# G32R501 register map
Vendor: Geehy Semiconductor Co., Ltd.; Series: G32R5; File version: 1.0
CPU: CM55 r0p1, little endian, MPU, FPU, double-precision FPU, DSP, VTOR, 4 interrupt priority bits
Registers are 32-bit, read-write, reset 0x0 unless marked. A register's access mark holds for its fields unless they carry their own. Offsets are from the block's base; [hi:lo] are bit positions; {n}, {i} and the like mark numbered series.

## GPIOCTRL — GPIO CTRL Registers
Base 0x40030000
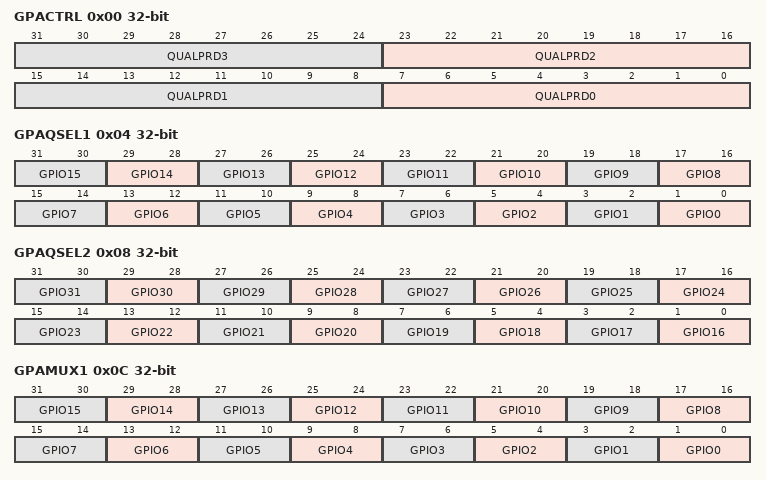
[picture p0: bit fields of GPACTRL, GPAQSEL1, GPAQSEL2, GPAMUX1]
0x00 GPACTRL — GPIO A Qualification Sampling Period (GPIO0 to GPIO31)
  [8n+7:8n] QUALPRD{n} (n=0..3) — GPIO{8n} to GPIO{8n+7} sampling cycle
0x04 GPAQSEL1 — GPIO A Qualification Type (GPIO0 to GPIO15)
  [2n+1:2n] GPIO{n} (n=0..15) — GPIO{n} Input type
0x08 GPAQSEL2 — GPIO A Qualification Type (GPIO16 to GPIO31)
  [2n-31:2n-32] GPIO{n} (n=16..31) — GPIO{n} Input type
0x0C GPAMUX1 — GPIO A Peripheral Mux (GPIO0 to GPIO15)
  [2n+1:2n] GPIO{n} (n=0..15) — GPIO{n} peripheral mux configuration in the low 2 bits
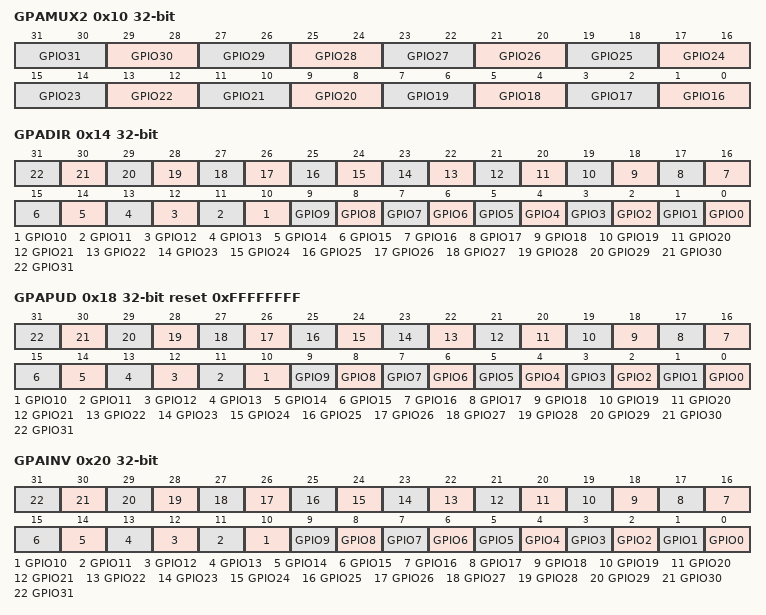
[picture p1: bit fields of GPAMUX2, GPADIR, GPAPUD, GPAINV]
0x10 GPAMUX2 — GPIO A Peripheral Mux (GPIO16 to GPIO31)
  [2n-31:2n-32] GPIO{n} (n=16..31) — GPIO{n} peripheral mux configuration in the low 2 bits
0x14 GPADIR — GPIO A Direction (GPIO0 to GPIO31)
  [n] GPIO{n} (n=0..31) — GPIO{n} Data direction
0x18 GPAPUD reset 0xFFFFFFFF — GPIO A Pull-Up Disable (GPIO0 to GPIO31)
  [n] GPIO{n} (n=0..31) — GPIO{n} Pull-up disable
0x20 GPAINV — GPIO A Input Inversion (GPIO0 to GPIO31)
  [n] GPIO{n} (n=0..31) — GPIO{n} Input inversion
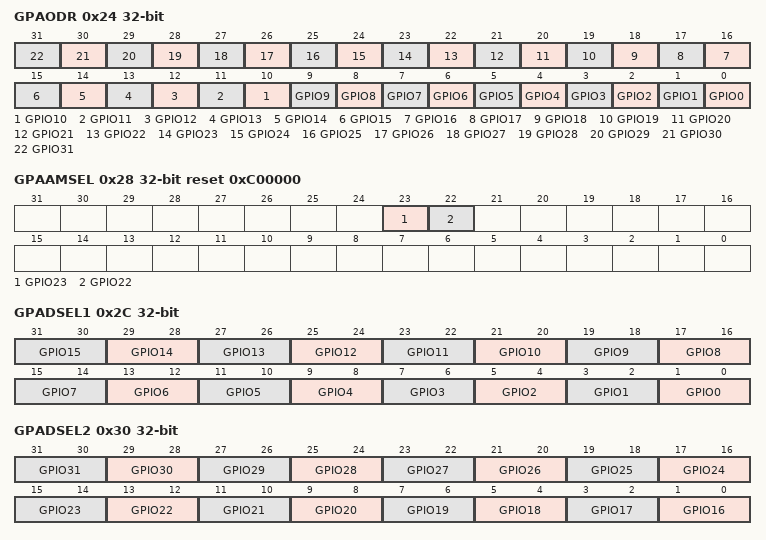
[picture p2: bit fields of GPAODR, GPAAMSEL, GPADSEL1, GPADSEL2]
0x24 GPAODR — GPIO A Open Drain Output Mode (GPIO0 to GPIO31)
  [n] GPIO{n} (n=0..31) — GPIO{n} Open-drain output mode
0x28 GPAAMSEL reset 0xC00000 — GPIO A Analog Mode Select (GPIO0 to GPIO31)
  [23] GPIO23 — Analog mode select for GPIO23
  [22] GPIO22 — Analog mode select for GPIO22
0x2C GPADSEL1 — GPIO A driver capability selection register 1
  [2n+1:2n] GPIO{n} (n=0..15) — Driver capability select for GPIO{n}
0x30 GPADSEL2 — GPIO A driver capability selection register 2
  [2n-31:2n-32] GPIO{n} (n=16..31) — Driver capability select for GPIO{n}
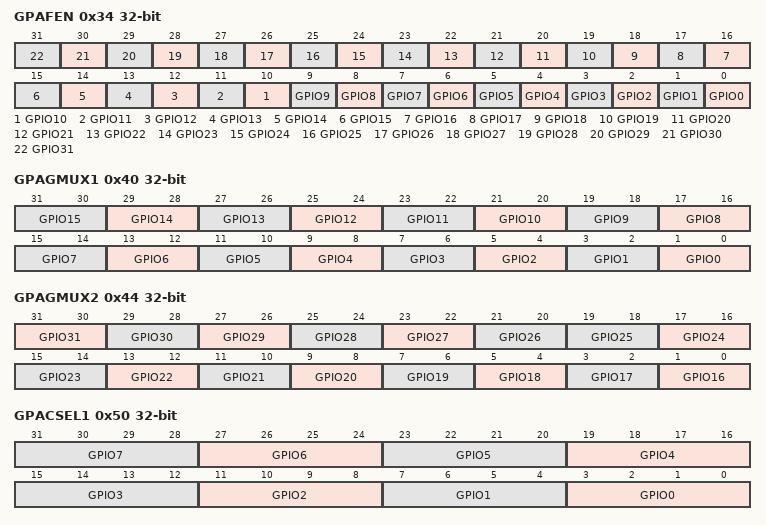
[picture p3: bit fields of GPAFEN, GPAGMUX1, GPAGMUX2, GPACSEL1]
0x34 GPAFEN — GPIO A maximum output frequency enable register
  [n] GPIO{n} (n=0..31) — GPIO{n} Maximum Output Frequency Enable
0x40 GPAGMUX1 — GPIO A Peripheral Group Mux (GPIO0 to GPIO15)
  [2n+1:2n] GPIO{n} (n=0..15) — GPIO{n} peripheral mux configuration in the High 2 bits
0x44 GPAGMUX2 — GPIO A Peripheral Group Mux (GPIO16 to GPIO31)
  [2n-31:2n-32] GPIO{n} (n=27..31) — GPIO{n} peripheral mux configuration in the High 2 bits
  [21:20] GPIO26 — GPIO126 peripheral mux configuration in the High 2 bits
  [2n-31:2n-32] GPIO{n} (n=16..25) — GPIO{n} peripheral mux configuration in the High 2 bits
0x50 GPACSEL1 — GPIO A Master Core Select (GPIO0 to GPIO7)
  [4n+3:4n] GPIO{n} (n=0..7) — GPIO{n} Master core select
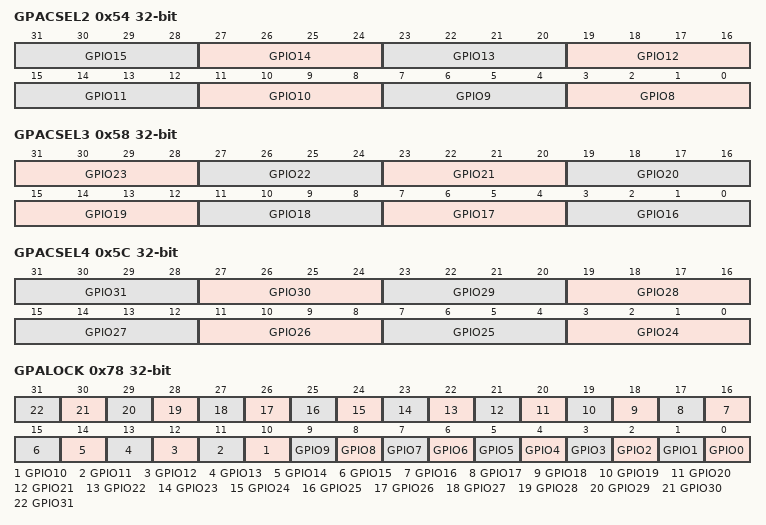
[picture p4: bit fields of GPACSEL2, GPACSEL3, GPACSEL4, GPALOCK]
0x54 GPACSEL2 — GPIO A Master Core Select (GPIO8 to GPIO15)
  [4n-29:4n-32] GPIO{n} (n=8..15) — GPIO{n} Master core select
0x58 GPACSEL3 — GPIO A Master Core Select (GPIO16 to GPIO23)
  [31:28] GPIO23 — GPIO22 Master core select
  [4n-61:4n-64] GPIO{n} (n=16..22) — GPIO{n} Master core select
0x5C GPACSEL4 — GPIO A Master Core Select (GPIO24 to GPIO31)
  [4n-93:4n-96] GPIO{n} (n=24..31) — GPIO{n} Master core select
0x78 GPALOCK — GPIO A Lock Register (GPIO0 to GPIO31)
  [n] GPIO{n} (n=0..31) — GPIO{n} Configuration lock
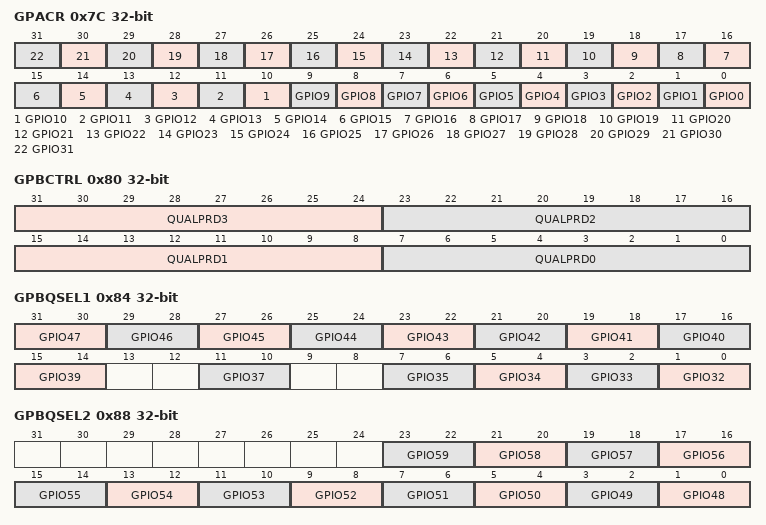
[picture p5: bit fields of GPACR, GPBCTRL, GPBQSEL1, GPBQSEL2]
0x7C GPACR — GPIO A Lock Commit Register (GPIO0 to GPIO31)
  [n] GPIO{n} (n=0..31) — GPIO{n} lock is locked
0x80 GPBCTRL — GPIO B Qualification Sampling Period (GPIO32 to GPIO59)
  [31:24] QUALPRD3 — GPIO56 to GPIO59 sampling cycle
  [23:16] QUALPRD2 — GPIO48 to GPIO55 sampling cycle
  [15:8] QUALPRD1 — GPIO40 to GPIO47 sampling cycle
  [7:0] QUALPRD0 — GPIO32 to GPIO39 sampling cycle
0x84 GPBQSEL1 — GPIO B Qualification Type (GPIO32 to GPIO47)
  [2n-63:2n-64] GPIO{n} (n=39..47) — GPIO{n} Input type
  [11:10] GPIO37 — GPIO37 Input type
  [2n-63:2n-64] GPIO{n} (n=32..35) — GPIO{n} Input type
0x88 GPBQSEL2 — GPIO B Qualification Type (GPIO48 to GPIO63)
  [2n-95:2n-96] GPIO{n} (n=48..59) — GPIO{n} Input type
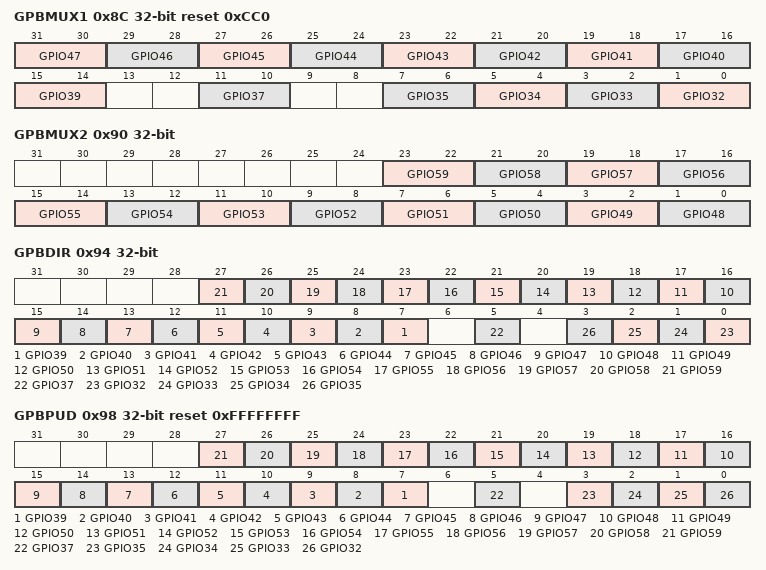
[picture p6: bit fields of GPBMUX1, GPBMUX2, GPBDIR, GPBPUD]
0x8C GPBMUX1 reset 0xCC0 — GPIO B Peripheral Mux (GPIO32 to GPIO47)
  [2n-63:2n-64] GPIO{n} (n=39..47) — GPIO{n} peripheral mux configuration in the low 2 bits
  [11:10] GPIO37 — GPIO37 peripheral mux configuration in the low 2 bits
  [2n-63:2n-64] GPIO{n} (n=32..35) — GPIO{n} peripheral mux configuration in the low 2 bits
0x90 GPBMUX2 — GPIO B Peripheral Mux (GPIO48 to GPIO63)
  [23:22] GPIO59 — GPIO4859 peripheral mux configuration in the low 2 bits
  [2n-95:2n-96] GPIO{n} (n=48..58) — GPIO{n} peripheral mux configuration in the low 2 bits
0x94 GPBDIR — GPIO B Direction (GPIO32 to GPIO59)
  [n-32] GPIO{n} (n=39..59) — GPIO{n} Data direction
  [5] GPIO37 — GPIO37 Data direction
  [n-32] GPIO{n} (n=32..35) — GPIO{n} Data direction
0x98 GPBPUD reset 0xFFFFFFFF — GPIO B Pull-Up Disable (GPIO32 to GPIO59)
  [n-32] GPIO{n} (n=39..59) — GPIO{n} Pull-up disable
  [5] GPIO37 — GPIO37 Pull-up disable
  [3] GPIO35 — GPIO35 Pull-up disable
  [2] GPIO34 — GPIO34 Pull-up disable
  [1] GPIO33 — GPIO32 Pull-up disable
  [0] GPIO32 — GPIO32 Pull-up disable
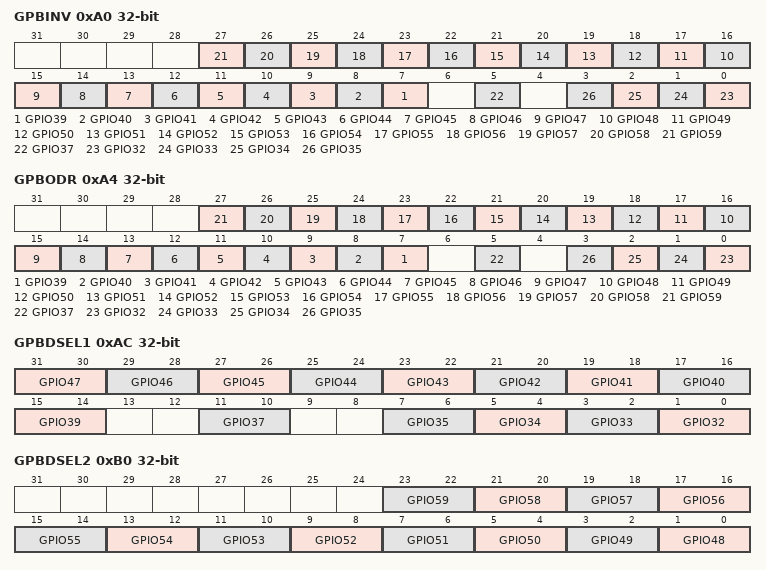
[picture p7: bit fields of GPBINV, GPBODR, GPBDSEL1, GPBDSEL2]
0xA0 GPBINV — GPIO B Input Inversion (GPIO32 to GPIO59)
  [n-32] GPIO{n} (n=39..59) — GPIO{n} Input inversion
  [5] GPIO37 — GPIO37 Input inversion
  [n-32] GPIO{n} (n=32..35) — GPIO{n} Input inversion
0xA4 GPBODR — GPIO B Open Drain Output Mode (GPIO32 to GPIO59)
  [n-32] GPIO{n} (n=39..59) — GPIO{n} Open-drain output mode
  [5] GPIO37 — GPIO37 Open-drain output mode
  [n-32] GPIO{n} (n=32..35) — GPIO{n} Open-drain output mode
0xAC GPBDSEL1 — GPIO B driver capability selection register 1
  [2n-63:2n-64] GPIO{n} (n=39..47) — Driver capability select for GPIO{n}
  [11:10] GPIO37 — Driver capability select for GPIO37
  [2n-63:2n-64] GPIO{n} (n=32..35) — Driver capability select for GPIO{n}
0xB0 GPBDSEL2 — GPIO B driver capability selection register 2
  [2n-95:2n-96] GPIO{n} (n=48..59) — Driver capability select for GPIO{n}
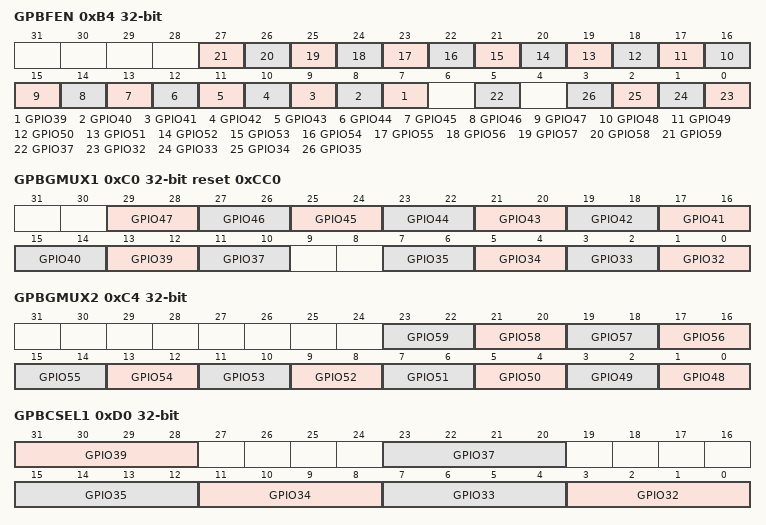
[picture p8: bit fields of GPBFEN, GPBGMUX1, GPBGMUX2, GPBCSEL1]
0xB4 GPBFEN — GPIO B maximum output frequency enable register
  [n-32] GPIO{n} (n=39..59) — GPIO{n} Maximum Output Frequency Enable
  [5] GPIO37 — GPIO37 Maximum Output Frequency Enable
  [n-32] GPIO{n} (n=32..35) — GPIO{n} Maximum Output Frequency Enable
0xC0 GPBGMUX1 reset 0xCC0 — GPIO B Peripheral Group Mux (GPIO32 to GPIO47)
  [2n-65:2n-66] GPIO{n} (n=39..47) — GPIO{n} peripheral mux configuration in the High 2 bits
  [11:10] GPIO37 — GPIO37 peripheral mux configuration in the High 2 bits
  [2n-63:2n-64] GPIO{n} (n=32..35) — GPIO{n} peripheral mux configuration in the High 2 bits
0xC4 GPBGMUX2 — GPIO B Peripheral Group Mux (GPIO48 to GPIO63)
  [2n-95:2n-96] GPIO{n} (n=48..59) — GPIO{n} peripheral mux configuration in the High 2 bits
0xD0 GPBCSEL1 — GPIO B Master Core Select (GPIO32 to GPIO39)
  [31:28] GPIO39 — GPIO39 Master core select
  [23:20] GPIO37 — GPIO37 Master core select
  [4n-125:4n-128] GPIO{n} (n=32..35) — GPIO{n} Master core select
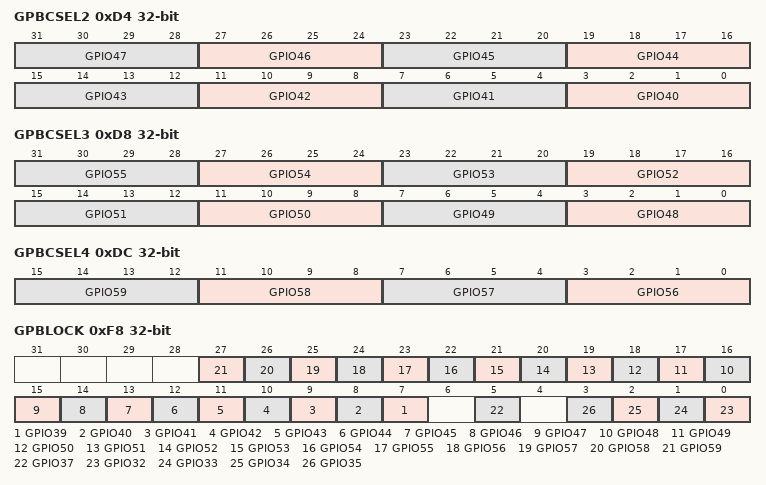
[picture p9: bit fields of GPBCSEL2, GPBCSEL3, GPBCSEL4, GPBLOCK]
0xD4 GPBCSEL2 — GPIO B Master Core Select (GPIO40 to GPIO47)
  [4n-157:4n-160] GPIO{n} (n=40..47) — GPIO{n} Master core select
0xD8 GPBCSEL3 — GPIO B Master Core Select (GPIO48 to GPIO55)
  [4n-189:4n-192] GPIO{n} (n=48..55) — GPIO{n} Master core select
0xDC GPBCSEL4 — GPIO B Master Core Select (GPIO56 to GPIO63)
  [4n-221:4n-224] GPIO{n} (n=56..59) — GPIO{n} Master core select
0xF8 GPBLOCK — GPIO B Lock Register (GPIO32 to GPIO59)
  [n-32] GPIO{n} (n=39..59) — GPIO{n} Configuration lock
  [5] GPIO37 — GPIO37 Configuration lock
  [n-32] GPIO{n} (n=32..35) — GPIO{n} Configuration lock
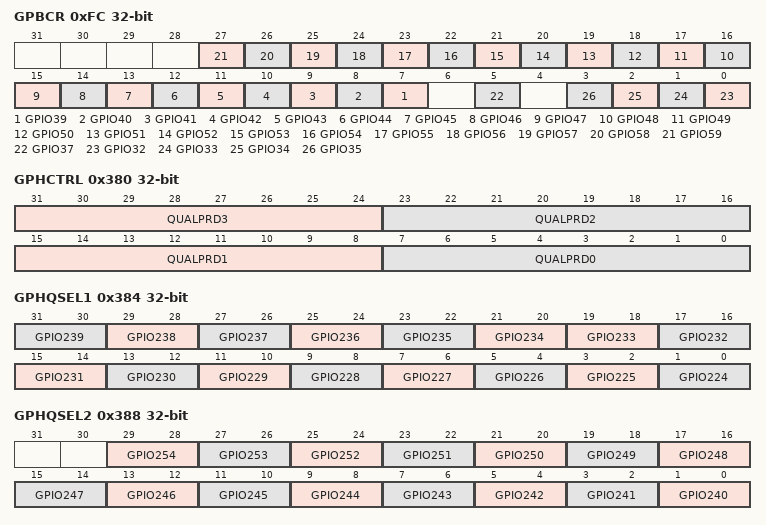
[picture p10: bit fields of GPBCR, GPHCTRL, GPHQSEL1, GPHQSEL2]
0xFC GPBCR — GPIO B Lock Commit Register (GPIO32 to GPIO59)
  [n-32] GPIO{n} (n=39..59) — GPIO{n} lock is locked
  [5] GPIO37 — GPIO37 lock is locked
  [n-32] GPIO{n} (n=32..35) — GPIO{n} lock is locked
0x380 GPHCTRL — GPIO H Qualification Sampling Period (GPIO224 to GPIO255)
  [31:24] QUALPRD3 — GPIO248 to GPIO254 sampling cycle
  [23:16] QUALPRD2 — GPIO240 to GPIO247 sampling cycle
  [15:8] QUALPRD1 — GPIO232 to GPIO239 sampling cycle
  [7:0] QUALPRD0 — GPIO224 to GPIO231 sampling cycle
0x384 GPHQSEL1 — GPIO H Qualification Type (GPIO224 to GPIO239)
  [2n-447:2n-448] GPIO{n} (n=234..239) — GPIO{n} Input type
  [19:18] GPIO233 — GPIO2333 Input type
  [2n-447:2n-448] GPIO{n} (n=224..232) — GPIO{n} Input type
0x388 GPHQSEL2 — GPIO H Qualification Type (GPIO240 to GPIO255)
  [2n-479:2n-480] GPIO{n} (n=240..254) — GPIO{n} Input type
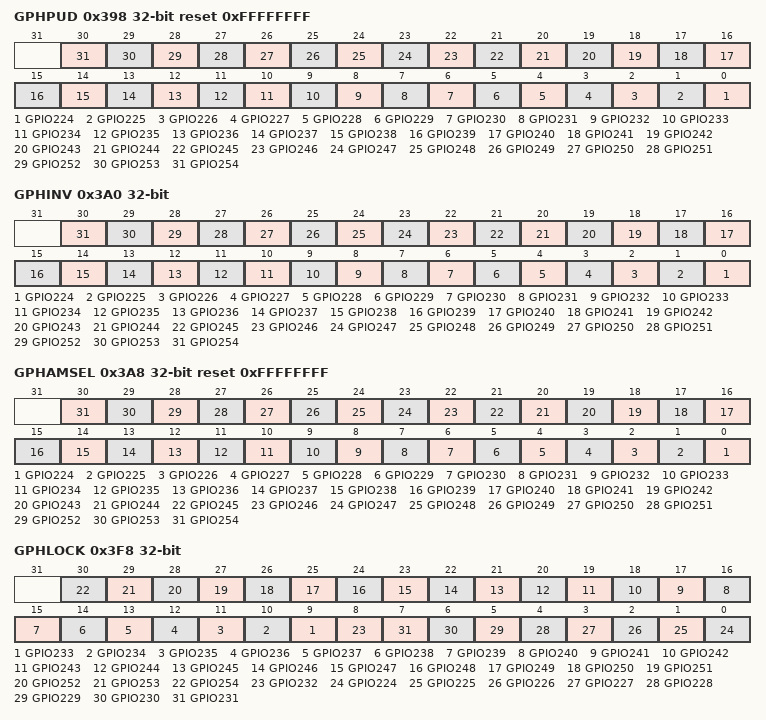
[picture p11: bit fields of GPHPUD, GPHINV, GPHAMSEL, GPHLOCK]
0x398 GPHPUD reset 0xFFFFFFFF — GPIO H Pull-Up Disable (GPIO224 to GPIO255)
  [n-224] GPIO{n} (n=224..254) — GPIO{n} Pull-up disable
0x3A0 GPHINV — GPIO H Input Inversion (GPIO224 to GPIO255)
  [n-224] GPIO{n} (n=224..254) — GPIO{n} Input inversion
0x3A8 GPHAMSEL reset 0xFFFFFFFF — GPIO H Analog Mode Select (GPIO224 to GPIO255)
  [n-224] GPIO{n} (n=224..254) — Analog mode select for GPIO{n}
0x3F8 GPHLOCK — GPIO H Lock Register (GPIO224 to GPIO255)
  [n-224] GPIO{n} (n=233..254) — GPIO{n} Configuration lock
  [8] GPIO232 — GPIO233 Configuration lock
  [n-224] GPIO{n} (n=224..231) — GPIO{n} Configuration lock
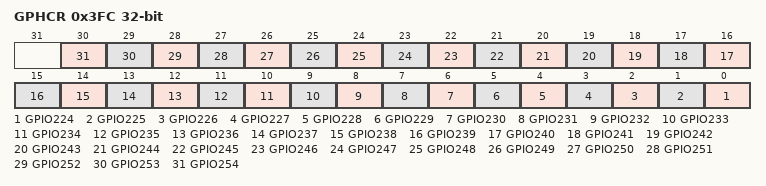
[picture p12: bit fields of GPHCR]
0x3FC GPHCR — GPIO H Lock Commit Register (GPIO224 to GPIO255)
  [n-224] GPIO{n} (n=224..254) — GPIO{n} lock is locked
